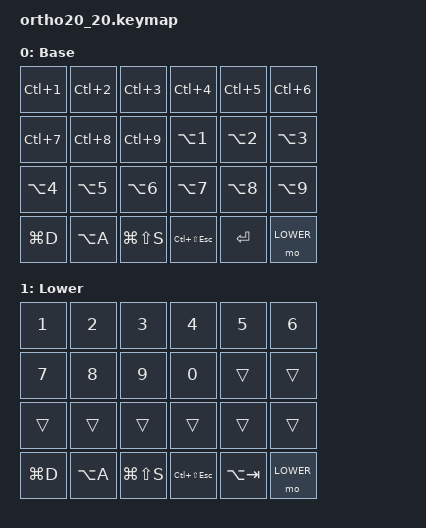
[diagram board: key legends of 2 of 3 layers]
#include <behaviors.dtsi>
#include <dt-bindings/zmk/keys.h>
#include <dt-bindings/zmk/bt.h>
#include <dt-bindings/zmk/outputs.h>

#define BASE 0
#define LOWER 1
#define RAISE 2

/ {
    combos {
        compatible = "zmk,combos";
        combo_studio_unlock {
            timeout-ms = <50>;
            key-positions = <40 43>;
            bindings = <&studio_unlock>;
        };
    };

    keymap {
        compatible = "zmk,keymap";

        default_layer {
            display-name = "Base";
            // -----------------------------------------------------------
            // | ESC | Q  | W  | E  | R  | T  | Y  | U  | I  | O  | P  | BSPC|
            // | SHF | A  | S  | D  | F  | G  | H  | J  | K  | L  | ;  | DEL |
            // | TAB | Z  | X  | C  | V  | B  | N  | M  | ,  | .  | UP | /   |
            // | CTL | WIN| ALT| WIN| LWR| SPC| ENT| RSE| GUI| LFT| DWN| RGT |
            // -----------------------------------------------------------
            bindings = <
                &kp LC(N1)    &kp LC(N2)    &kp LC(N3)    &kp LC(N4)    &kp LC(N5)    &kp LC(N6)
                &kp LC(N7)    &kp LC(N8)    &kp LC(N9)    &kp LA(N1)    &kp LA(N2)    &kp LA(N3)
                &kp LA(N4)    &kp LA(N5)    &kp LA(N6)    &kp LA(N7)    &kp LA(N8)    &kp LA(N9)
                &kp LG(D)     &kp LA(A)     &kp LG(LS(S)) &kp LC(LS(ESC)) &kp RET &mo LOWER
            >;
        };

        lower_layer {
            display-name = "Lower";
            // -----------------------------------------------------------
            // |  `  | 1  | 2  | 3  | 4  | 5  | 6  | 7  | 8  | 9  | 0  | BSPC|
            // | SHF | F1 | F2 | F3 | F4 | F5 | F6 | F7 | F8 | F9 | F10| DEL |
            // | TAB | F11| F12|    |    |    |    |    |    |    | PUP|    |
            // | CTL | WIN| ALT| WIN|    | ENT| ENT|    | GUI| HOM| PDN| END |
            // -----------------------------------------------------------
            bindings = <
                &kp N1    &kp N2    &kp N3    &kp N4    &kp N5    &kp N6
                &kp N7    &kp N8    &kp N9    &kp N0    &trans    &trans
                &trans    &trans    &trans    &trans    &trans    &trans
                &kp LG(D)     &kp LA(A)     &kp LG(LS(S)) &kp LC(LS(ESC)) &kp LA(TAB) &mo LOWER
            >;
        };

        raise_layer {
            display-name = "Raise";
            // -----------------------------------------------------------
            // |  ~  | !  | @  | #  | $  | %  | ^  | &  | *  | (  | )  | BSPC|
            // | SHF |    |    |    |    |    | -  | =  | [  | ]  | \  | DEL |
            // | TAB |    |    |    |    |    | _  | +  | {  | }  | PUP| |   |
            // | CTL | WIN| ALT| WIN|    | ENT| ENT|    | GUI| HOM| PDN| END |
            // -----------------------------------------------------------
            bindings = <
                &kp TILDE &kp EXCL  &kp AT    &kp HASH  &kp DLLR  &kp PRCNT   &kp CARET &kp AMPS  &kp STAR   &kp LPAR  &kp RPAR  &kp BSPC
                &kp LSHFT &trans    &trans    &trans    &trans    &trans      &kp MINUS &kp EQUAL &kp LBKT   &kp RBKT  &kp BSLH  &kp DEL
                &kp TAB   &trans    &trans    &trans    &trans    &trans      &kp UNDER &kp PLUS  &kp LBRC   &kp RBRC  &kp PG_UP &kp PIPE
                &kp LCTRL &kp LGUI  &kp LALT  &kp RGUI  &trans    &kp RET     &kp RET   &trans    &kp RGUI   &kp HOME  &kp PG_DN &kp END
            >;
        };
    };
};
